# daric register map
Vendor: cramium
Registers are 32-bit, read-write, reset 0x0 unless marked. A register's access mark holds for its fields unless they carry their own. Offsets are from the block's base; [hi:lo] are bit positions.

## AES
Base 0x4002D000
0x00 SFR_CRFUNC — See file:///F:/code/cram-nto/modules/crypto_top/rtl/aes.sv
  [7:0] sfr_crfunc — sfr_crfunc read/write control register
0x04 SFR_AR — See file:///F:/code/cram-nto/modules/crypto_top/rtl/aes.sv
  [31:0] sfr_ar — sfr_ar performs action on write of value: 0x5a
0x08 SFR_SRMFSM — See file:///F:/code/cram-nto/modules/crypto_top/rtl/aes.sv
  [7:0] sfr_srmfsm — sfr_srmfsm read only status register
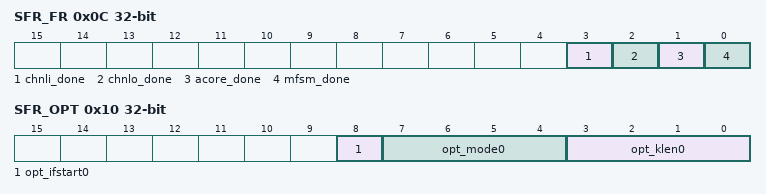
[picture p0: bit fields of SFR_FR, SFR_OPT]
0x0C SFR_FR — See file:///F:/code/cram-nto/modules/crypto_top/rtl/aes.sv
  [3] chnli_done — chnli_done flag register. `1` means event happened, write back `1` in respective bit position to clear the flag
  [2] chnlo_done — chnlo_done flag register. `1` means event happened, write back `1` in respective bit position to clear the flag
  [1] acore_done — acore_done flag register. `1` means event happened, write back `1` in respective bit position to clear the flag
  [0] mfsm_done — mfsm_done flag register. `1` means event happened, write back `1` in respective bit position to clear the flag
0x10 SFR_OPT — See file:///F:/code/cram-nto/modules/crypto_top/rtl/aes.sv
  [8] opt_ifstart0 — opt_ifstart0 read/write control register
  [7:4] opt_mode0 — opt_mode0 read/write control register
  [3:0] opt_klen0 — opt_klen0 read/write control register
0x14 SFR_OPT1 — See file:///F:/code/cram-nto/modules/crypto_top/rtl/aes.sv
  [15:0] sfr_opt1 — sfr_opt1 read/write control register
0x18 SFR_OPTLTX — See file:///F:/code/cram-nto/modules/crypto_top/rtl/aes.sv
  [5:0] sfr_optltx — sfr_optltx read/write control register
0x20 SFR_MASKSEED — See file:///F:/code/cram-nto/modules/crypto_top/rtl/aes.sv
  [31:0] sfr_maskseed — sfr_maskseed read/write control register
0x24 SFR_MASKSEEDAR — See file:///F:/code/cram-nto/modules/crypto_top/rtl/aes.sv
  [31:0] sfr_maskseedar — sfr_maskseedar performs action on write of value: 0x5a
0x30 SFR_SEGPTR_PTRID_IV — See file:///F:/code/cram-nto/modules/crypto_top/rtl/aes.sv
  [11:0] PTRID_IV — cr_segptrstart read/write control register
0x34 SFR_SEGPTR_PTRID_AKEY — See file:///F:/code/cram-nto/modules/crypto_top/rtl/aes.sv
  [11:0] PTRID_AKEY — cr_segptrstart read/write control register
0x38 SFR_SEGPTR_PTRID_AIB — See file:///F:/code/cram-nto/modules/crypto_top/rtl/aes.sv
  [11:0] PTRID_AIB — cr_segptrstart read/write control register
0x3C SFR_SEGPTR_PTRID_AOB — See file:///F:/code/cram-nto/modules/crypto_top/rtl/aes.sv
  [11:0] PTRID_AOB — cr_segptrstart read/write control register

## COMBOHASH
Base 0x4002B000
0x00 SFR_CRFUNC — See file:///F:/code/cram-nto/modules/crypto_top/rtl/combohasha.sv
  [7:0] cr_func — cr_func read/write control register
0x04 SFR_AR — See file:///F:/code/cram-nto/modules/crypto_top/rtl/combohasha.sv
  [31:0] sfr_ar — sfr_ar performs action on write of value: 0x5a
0x08 SFR_SRMFSM — See file:///F:/code/cram-nto/modules/crypto_top/rtl/combohasha.sv
  [7:0] mfsm — mfsm read only status register
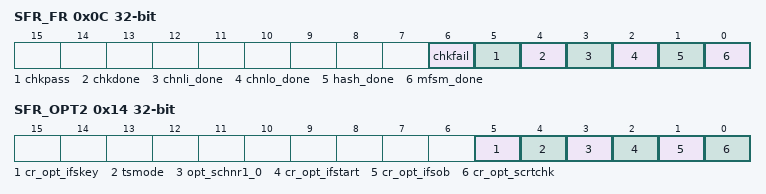
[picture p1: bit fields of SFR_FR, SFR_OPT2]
0x0C SFR_FR — See file:///F:/code/cram-nto/modules/crypto_top/rtl/combohasha.sv
  [6] chkfail — chkfail flag register. `1` means event happened, write back `1` in respective bit position to clear the flag
  [5] chkpass — chkpass flag register. `1` means event happened, write back `1` in respective bit position to clear the flag
  [4] chkdone — chkdone flag register. `1` means event happened, write back `1` in respective bit position to clear the flag
  [3] chnli_done — chnli_done flag register. `1` means event happened, write back `1` in respective bit position to clear the flag
  [2] chnlo_done — chnlo_done flag register. `1` means event happened, write back `1` in respective bit position to clear the flag
  [1] hash_done — hash_done flag register. `1` means event happened, write back `1` in respective bit position to clear the flag
  [0] mfsm_done — mfsm_done flag register. `1` means event happened, write back `1` in respective bit position to clear the flag
0x10 SFR_OPT1 — See file:///F:/code/cram-nto/modules/crypto_top/rtl/combohasha.sv
  [15:0] cr_opt_hashcnt — cr_opt_hashcnt read/write control register
0x14 SFR_OPT2 — See file:///F:/code/cram-nto/modules/crypto_top/rtl/combohasha.sv
  [5] cr_opt_ifskey — cr_opt.ifskey read/write control register
  [4] tsmode — tsmode read/write control register
  [3] opt_schnr1_0 — opt_schnr[1:0] read/write control register
  [2] cr_opt_ifstart — cr_opt.ifstart read/write control register
  [1] cr_opt_ifsob — cr_opt.ifsob read/write control register
  [0] cr_opt_scrtchk — cr_opt.scrtchk read/write control register
0x18 SFR_OPT3 — See file:///F:/code/cram-nto/modules/crypto_top/rtl/combohasha.sv
  [7:0] sfr_opt3 — sfr_opt3 read/write control register
0x1C SFR_BLKT0 — See file:///F:/code/cram-nto/modules/crypto_top/rtl/combohasha.sv
  [7:0] sfr_blkt0 — sfr_blkt0 read/write control register
0x20 SFR_SEGPTR_SEGID_LKEY — See file:///F:/code/cram-nto/modules/crypto_top/rtl/combohasha.sv
  [11:0] SEGID_LKEY — cr_segptrstart read/write control register
0x24 SFR_SEGPTR_SEGID_KEY — See file:///F:/code/cram-nto/modules/crypto_top/rtl/combohasha.sv
  [11:0] SEGID_KEY — cr_segptrstart read/write control register
0x2C SFR_SEGPTR_SEGID_SCRT — See file:///F:/code/cram-nto/modules/crypto_top/rtl/combohasha.sv
  [11:0] SEGID_SCRT — cr_segptrstart read/write control register
0x30 SFR_SEGPTR_SEGID_MSG — See file:///F:/code/cram-nto/modules/crypto_top/rtl/combohasha.sv
  [11:0] SEGID_MSG — cr_segptrstart read/write control register
0x34 SFR_SEGPTR_SEGID_HOUT — See file:///F:/code/cram-nto/modules/crypto_top/rtl/combohasha.sv
  [11:0] SEGID_HOUT — cr_segptrstart read/write control register
0x3C SFR_SEGPTR_SEGID_HOUT2 — See file:///F:/code/cram-nto/modules/crypto_top/rtl/combohasha.sv
  [11:0] SEGID_HOUT2 — cr_segptrstart read/write control register
0x60 SFR_KEYIDX — See file:///F:/code/cram-nto/modules/crypto_top/rtl/combohasha.sv
  [9:0] sfr_keyidx — sfr_keyidx read/write control register
